# PIC32CK0512SG00100 register map
Vendor: Microchip Technology; Series: PIC32CKSG00; File version: 0
CPU: CM33 r0p0, little endian, MPU, FPU, DSP, 3 interrupt priority bits, 158 interrupts, 23 SAU regions
Registers are 32-bit, read-write, reset 0x0 unless marked. A register's access mark holds for its fields unless they carry their own. Offsets are from the block's base; [hi:lo] are bit positions; lines under a group give offsets from that group; {n}, {i} and the like mark numbered series; 'fields as' and 'values as' point back to an identical list.

## PORT — Port Module
Base 0x44800000
Same registers: PORT_SEC 0x44801000
{0x0+0x80*i} GROUP[{i}] (i=0..3) group
  0x00 DIR — Data Direction
    [31:0] DIR — Port Data Direction
  0x04 DIRCLR — Data Direction Clear
    [31:0] DIRCLR — Port Data Direction Clear
  0x08 DIRSET — Data Direction Set
    [31:0] DIRSET — Port Data Direction Set
  0x0C DIRTGL — Data Direction Toggle
    [31:0] DIRTGL — Port Data Direction Toggle
  0x10 OUT — Data Output Value
    [31:0] OUT — PORT Data Output Value
  0x14 OUTCLR — Data Output Value Clear
    [31:0] OUTCLR — PORT Data Output Value Clear
  0x18 OUTSET — Data Output Value Set
    [31:0] OUTSET — PORT Data Output Value Set
  0x1C OUTTGL — Data Output Value Toggle
    [31:0] OUTTGL — PORT Data Output Value Toggle
  0x20 IN ro — Data Input Value
    [31:0] IN — PORT Data Input Value
  0x24 CTRL — Control
    [31:0] SAMPLING — Input Sampling Mode
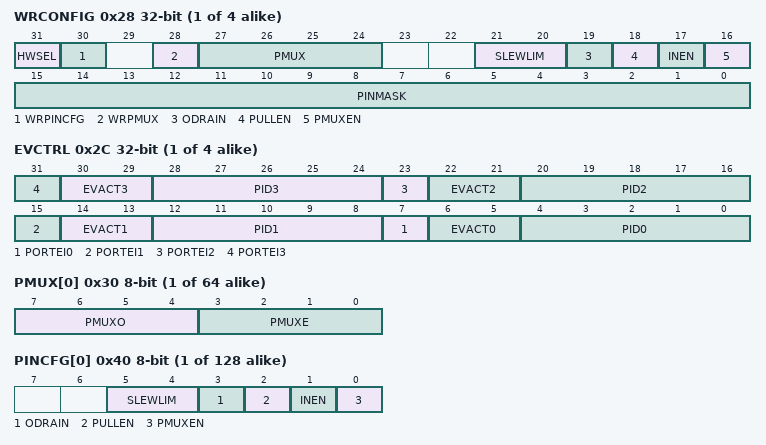
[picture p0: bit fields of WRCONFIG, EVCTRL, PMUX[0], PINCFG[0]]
  0x28 WRCONFIG wo — Write Configuration
    [31] HWSEL — Half-Word Select
    [30] WRPINCFG — Write PINCFG
    [28] WRPMUX — Write PMUX
    [27:24] PMUX — Peripheral Multiplexing
    [21:20] SLEWLIM — Output Driver Slew Rate Selection
    [19] ODRAIN — Open Drain Output
    [18] PULLEN — Pull Enable
    [17] INEN — Input Enable
    [16] PMUXEN — Peripheral Multiplexer Enable
    [15:0] PINMASK — Pin Mask for Multiple Pin Configuration
  0x2C EVCTRL — Event Input Control
    [8n+7] PORTEI{n} (n=0..3) — PORT Event Input Enable {n}
    [30:29] EVACT3 — PORT Event Action 3
    [8n+4:8n] PID{n} (n=0..3) — PORT Event Pin Identifier {n}
    [22:21] EVACT2 — PORT Event Action 2
    [14:13] EVACT1 — PORT Event Action 1
    [6:5] EVACT0 — PORT Event Action 0
      0=OUT (Event output to pin); 1=SET (Set output register of pin on event); 2=CLR (Clear output register of pin on event); 3=TGL (Toggle output register of pin on event)
  {0x30+j} PMUX[{j}] (j=0..15) 8-bit — Peripheral Multiplexing
    [7:4] PMUXO — Peripheral Multiplexing for Odd-Numbered Pin
      0=A (External Interrupts); 1=B (ADC and Analog Comparator); 2=C (SERCOMn (UART, I2C, SPI)); 3=D (SERCOMn Alt (UART, I2C, SPI)); 4=E (External Bus Interface); 5=F (Timer/Counter controller); 6=G (Timer/Counter controller and Positional Decoder Alt); 7=H (SQI/CAN/USB/CM33 Trace); 8=I (SD/MMC Host Controller (Memory Card Interface)); 9=J (SPI_IXS Audio); 10=K (Parallel Capture Controller); 11=L (Ethernet); 12=M (GCLK/CCL/AC Alt); 13=P (Peripheral Touch Controller and JTAG/SWD Debug Interfaces)
    [3:0] PMUXE — Peripheral Multiplexing for Even-Numbered Pin
      values as PMUXO
  {0x40+j} PINCFG[{j}] (j=0..31) 8-bit — Pin Configuration
    [5:4] SLEWLIM — Output Driver Slew Rate Selection
      0=FAST (Slew rate control disabled (fast rise/fall time operation)); 1=SLOW4 (Slew rate control enabled (4x slower)); 2=SLOW8 (Slew rate control enabled (8x slower)); 3=SLOW12 (Slew rate control enabled (12x slower))
    [3] ODRAIN — Open Drain Output
    [2] PULLEN — Pull Enable
    [1] INEN — Input Enable
    [0] PMUXEN — Peripheral Multiplexer Enable
  0x60 INTENCLR write-1-clears — Interrupt Enable Clear
    [0] NSCHK — Non-Secure Check Interrupt Enable
  0x64 INTENSET write-1-sets — Interrupt Enable Set
    [0] NSCHK — Non-Secure Check Interrupt Enable
  0x68 INTFLAG write-1-clears — Interrupt Flag Status and Clear
    [0] NSCHK — Non-Secure Check
  0x6C NONSEC — Security Attribution
    [31:0] NONSEC — Port Security Attribution
  0x70 NSCHK — Security Attribution Check
    [31:0] NSCHK — Port Security Attribution Check

## PRM — Boot ROM Controller
Base 0x4480A000
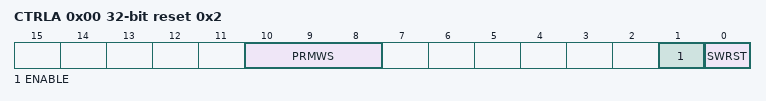
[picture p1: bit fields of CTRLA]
0x00 CTRLA reset 0x2 — CONTROL A REGISTER
  [10:8] PRMWS — ROM ACCESS TIME WAIT STATE
  [1] ENABLE — ENABLE BIT
  [0] SWRST — SOFTWARE RESET BIT
